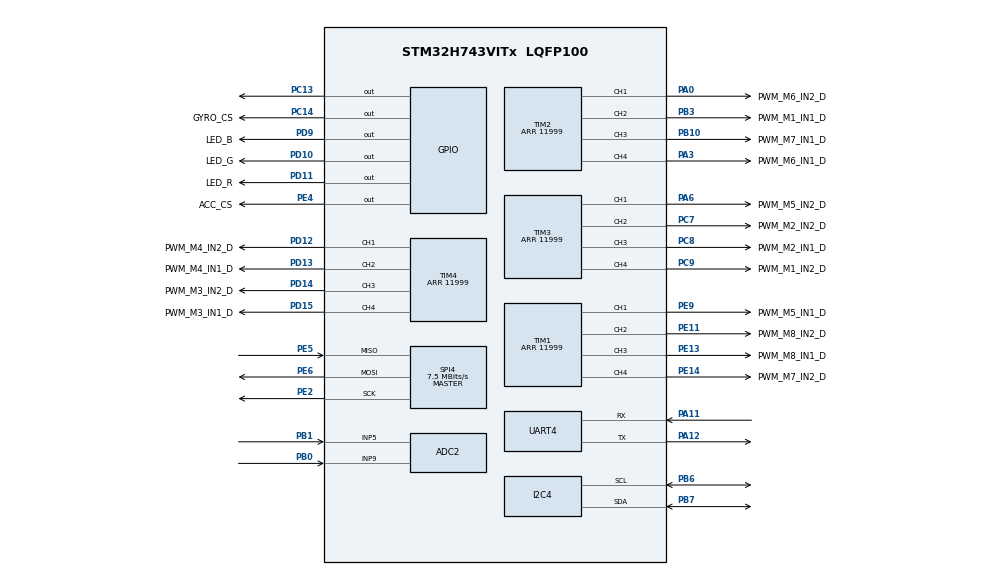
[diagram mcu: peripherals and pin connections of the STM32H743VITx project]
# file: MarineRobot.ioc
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ADC2.Channel-1\#ChannelRegularConversion=ADC_CHANNEL_9
ADC2.NbrOfConversionFlag=1
ADC2.OffsetNumber-1\#ChannelRegularConversion=ADC_OFFSET_NONE
ADC2.OffsetSignedSaturation-1\#ChannelRegularConversion=DISABLE
ADC2.Rank-1\#ChannelRegularConversion=1
ADC2.SamplingTime-1\#ChannelRegularConversion=ADC_SAMPLETIME_1CYCLE_5
CORTEX_M7.default_mode_Activation=1
FREERTOS.Tasks01=defaultTask,0,128,StartDefaultTask,Default,NULL,Dynamic,NULL,NULL
FREERTOS.configGENERATE_RUN_TIME_STATS=1
FREERTOS.configRECORD_STACK_HIGH_ADDRESS=1
FREERTOS.configUSE_STATS_FORMATTING_FUNCTIONS=1
FREERTOS.configUSE_TRACE_FACILITY=1
I2C4.Timing=0x307075B1
Mcu.Family=STM32H7
Mcu.Name=STM32H743VITx
Mcu.Package=LQFP100
NVIC.PriorityGroup=NVIC_PRIORITYGROUP_4
NVIC.TIM6_DAC_IRQn=true\:15\:0\:false\:false\:true\:false\:false\:true\:true
NVIC.TimeBase=TIM6_DAC_IRQn
NVIC.TimeBaseIP=TIM6
NVIC.UART4_IRQn=true\:5\:0\:false\:false\:true\:true\:true\:true\:true
PA0.GPIO_Label=PWM_M6_IN2_D
PA0.Signal=S_TIM2_CH1_ETR
PA11.Mode=Asynchronous
PA11.Signal=UART4_RX
PA12.Mode=Asynchronous
PA12.Signal=UART4_TX
PA13\ (JTMS/SWDIO).Mode=Serial_Wire
PA13\ (JTMS/SWDIO).Signal=DEBUG_JTMS-SWDIO
PA14\ (JTCK/SWCLK).Mode=Serial_Wire
PA14\ (JTCK/SWCLK).Signal=DEBUG_JTCK-SWCLK
PA3.GPIO_Label=PWM_M6_IN1_D
PA3.Signal=S_TIM2_CH4
PA6.GPIO_Label=PWM_M5_IN2_D
PA6.Signal=S_TIM3_CH1
PB0.Signal=ADCx_INP9
PB1.Signal=ADCx_INP5
PB10.GPIO_Label=PWM_M7_IN1_D
PB10.Signal=S_TIM2_CH3
PB3\ (JTDO/TRACESWO).GPIO_Label=PWM_M1_IN1_D
PB3\ (JTDO/TRACESWO).Signal=S_TIM2_CH2
PB6.Mode=I2C
PB6.Signal=I2C4_SCL
PB7.Mode=I2C
PB7.Signal=I2C4_SDA
PC12.Signal=UART5_TX
PC13.Signal=GPIO_Output
PC14-OSC32_IN\ (OSC32_IN).GPIO_Label=GYRO_CS
PC14-OSC32_IN\ (OSC32_IN).Signal=GPIO_Output
PC7.GPIO_Label=PWM_M2_IN2_D
PC7.Signal=S_TIM3_CH2
PC8.GPIO_Label=PWM_M2_IN1_D
PC8.Signal=S_TIM3_CH3
PC9.GPIO_Label=PWM_M1_IN2_D
PC9.Signal=S_TIM3_CH4
PD10.GPIO_Label=LED_G
PD10.Signal=GPIO_Output
PD11.GPIO_Label=LED_R
PD11.Signal=GPIO_Output
PD12.GPIO_Label=PWM_M4_IN2_D
PD12.Signal=S_TIM4_CH1
PD13.GPIO_Label=PWM_M4_IN1_D
PD13.Signal=S_TIM4_CH2
PD14.GPIO_Label=PWM_M3_IN2_D
PD14.Signal=S_TIM4_CH3
PD15.GPIO_Label=PWM_M3_IN1_D
PD15.Signal=S_TIM4_CH4
PD2.Signal=UART5_RX
PD9.GPIO_Label=LED_B
PD9.Signal=GPIO_Output
PE11.GPIO_Label=PWM_M8_IN2_D
PE11.Signal=S_TIM1_CH2
PE13.GPIO_Label=PWM_M8_IN1_D
PE13.Signal=S_TIM1_CH3
PE14.GPIO_Label=PWM_M7_IN2_D
PE14.Signal=S_TIM1_CH4
PE2.Mode=Full_Duplex_Master
PE2.Signal=SPI4_SCK
PE4.GPIO_Label=ACC_CS
PE4.Signal=GPIO_Output
PE5.Mode=Full_Duplex_Master
PE5.Signal=SPI4_MISO
PE6.Mode=Full_Duplex_Master
PE6.Signal=SPI4_MOSI
PE9.GPIO_Label=PWM_M5_IN1_D
PE9.Signal=S_TIM1_CH1
PH0-OSC_IN\ (PH0).Mode=HSE-External-Oscillator
PH0-OSC_IN\ (PH0).Signal=RCC_OSC_IN
PH1-OSC_OUT\ (PH1).Mode=HSE-External-Oscillator
PH1-OSC_OUT\ (PH1).Signal=RCC_OSC_OUT
ProjectManager.HeapSize=0x200
ProjectManager.StackSize=0x400
ProjectManager.TargetToolchain=CMake
RCC.ADCFreq_Value=80000000
RCC.APB1Freq_Value=120000000
RCC.APB2Freq_Value=120000000
RCC.APB3Freq_Value=120000000
RCC.APB4Freq_Value=120000000
RCC.CortexFreq_Value=480000000
RCC.D1PPRE=RCC_APB3_DIV2
RCC.D2PPRE1=RCC_APB1_DIV2
RCC.D2PPRE2=RCC_APB2_DIV2
RCC.D3PPRE=RCC_APB4_DIV2
RCC.DIVM1=2
RCC.DIVM2=2
RCC.DIVN1=60
RCC.DIVN2=10
RCC.HCLKFreq_Value=240000000
RCC.HPRE=RCC_HCLK_DIV2
RCC.HSE_VALUE=32000000
RCC.PLL2FRACN=0
RCC.PLLSourceVirtual=RCC_PLLSOURCE_HSE
RCC.SYSCLKFreq_VALUE=480000000
RCC.SYSCLKSource=RCC_SYSCLKSOURCE_PLLCLK
RCC.USBFreq_Value=480000000
SH.ADCx_INP5.0=ADC2_INP5,IN5-Single-Ended
SH.ADCx_INP9.0=ADC2_INP9,IN9-Single-Ended
SH.S_TIM1_CH1.0=TIM1_CH1,PWM Generation1 CH1
SH.S_TIM1_CH2.0=TIM1_CH2,PWM Generation2 CH2
SH.S_TIM1_CH3.0=TIM1_CH3,PWM Generation3 CH3
SH.S_TIM1_CH4.0=TIM1_CH4,PWM Generation4 CH4
SH.S_TIM2_CH1_ETR.0=TIM2_CH1,PWM Generation1 CH1
SH.S_TIM2_CH2.0=TIM2_CH2,PWM Generation2 CH2
SH.S_TIM2_CH3.0=TIM2_CH3,PWM Generation3 CH3
SH.S_TIM2_CH4.0=TIM2_CH4,PWM Generation4 CH4
SH.S_TIM3_CH1.0=TIM3_CH1,PWM Generation1 CH1
SH.S_TIM3_CH2.0=TIM3_CH2,PWM Generation2 CH2
SH.S_TIM3_CH3.0=TIM3_CH3,PWM Generation3 CH3
SH.S_TIM3_CH4.0=TIM3_CH4,PWM Generation4 CH4
SH.S_TIM4_CH1.0=TIM4_CH1,PWM Generation1 CH1
SH.S_TIM4_CH2.0=TIM4_CH2,PWM Generation2 CH2
SH.S_TIM4_CH3.0=TIM4_CH3,PWM Generation3 CH3
SH.S_TIM4_CH4.0=TIM4_CH4,PWM Generation4 CH4
SPI4.BaudRatePrescaler=SPI_BAUDRATEPRESCALER_16
SPI4.CalculateBaudRate=7.5 MBits/s
SPI4.DataSize=SPI_DATASIZE_8BIT
SPI4.Direction=SPI_DIRECTION_2LINES
SPI4.Mode=SPI_MODE_MASTER
SPI4.VirtualType=VM_MASTER
TIM1.Channel-PWM\ Generation1\ CH1=TIM_CHANNEL_1
TIM1.Channel-PWM\ Generation2\ CH2=TIM_CHANNEL_2
TIM1.Channel-PWM\ Generation3\ CH3=TIM_CHANNEL_3
TIM1.Channel-PWM\ Generation4\ CH4=TIM_CHANNEL_4
TIM1.Period=11999
TIM2.Channel-PWM\ Generation1\ CH1=TIM_CHANNEL_1
TIM2.Channel-PWM\ Generation2\ CH2=TIM_CHANNEL_2
TIM2.Channel-PWM\ Generation3\ CH3=TIM_CHANNEL_3
TIM2.Channel-PWM\ Generation4\ CH4=TIM_CHANNEL_4
TIM2.Period=11999
TIM3.Channel-PWM\ Generation1\ CH1=TIM_CHANNEL_1
TIM3.Channel-PWM\ Generation2\ CH2=TIM_CHANNEL_2
TIM3.Channel-PWM\ Generation3\ CH3=TIM_CHANNEL_3
TIM3.Channel-PWM\ Generation4\ CH4=TIM_CHANNEL_4
TIM3.Period=11999
TIM4.Channel-PWM\ Generation1\ CH1=TIM_CHANNEL_1
TIM4.Channel-PWM\ Generation2\ CH2=TIM_CHANNEL_2
TIM4.Channel-PWM\ Generation3\ CH3=TIM_CHANNEL_3
TIM4.Channel-PWM\ Generation4\ CH4=TIM_CHANNEL_4
TIM4.Period=11999
VP_FREERTOS_VS_CMSIS_V1.Mode=CMSIS_V1
VP_MEMORYMAP_VS_MEMORYMAP.Mode=CurAppReg
VP_SYS_VS_tim6.Mode=TIM6
VP_TIM1_VS_ClockSourceINT.Mode=Internal
VP_TIM2_VS_ClockSourceINT.Mode=Internal
VP_TIM3_VS_ClockSourceINT.Mode=Internal
VP_TIM4_VS_ClockSourceINT.Mode=Internal
board=custom

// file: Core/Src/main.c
/* USER CODE BEGIN Header */
/**
  ******************************************************************************
  * @file           : main.c
  * @brief          : Main program body
  ******************************************************************************
  * @attention
  *
  * Copyright (c) 2025 STMicroelectronics.
  * All rights reserved.
  *
  * This software is licensed under terms that can be found in the LICENSE file
  * in the root directory of this software component.
  * If no LICENSE file comes with this software, it is provided AS-IS.
  *
  ******************************************************************************
  */
/* USER CODE END Header */
#include "main.h"
#include "cmsis_os.h"
#include "adc.h"
#include "i2c.h"
#include "spi.h"
#include "tim.h"
#include "usart.h"
#include "gpio.h"

void SystemClock_Config(void);
static void MPU_Config(void);
void MX_FREERTOS_Init(void);

int main(void)
{

  /* MPU Configuration--------------------------------------------------------*/
  MPU_Config();

  /* MCU Configuration--------------------------------------------------------*/

  /* Reset of all peripherals, Initializes the Flash interface and the Systick. */
  HAL_Init();

  /* Configure the system clock */
  SystemClock_Config();

  /* Initialize all configured peripherals */
  MX_GPIO_Init();
  MX_TIM1_Init();
  MX_ADC2_Init();
  MX_I2C4_Init();
  MX_SPI4_Init();
  MX_TIM2_Init();
  MX_TIM3_Init();
  MX_TIM4_Init();
  MX_UART4_Init();

  /* Call init function for freertos objects (in cmsis_os2.c) */
  MX_FREERTOS_Init();

  /* Start scheduler */
  osKernelStart();

  /* We should never get here as control is now taken by the scheduler */

  /* Infinite loop */
  while (1)
  {

  }
}

void SystemClock_Config(void)
{
  RCC_OscInitTypeDef RCC_OscInitStruct = {0};
  RCC_ClkInitTypeDef RCC_ClkInitStruct = {0};

  /** Supply configuration update enable
  */
  HAL_PWREx_ConfigSupply(PWR_LDO_SUPPLY);

  /** Configure the main internal regulator output voltage
  */
  __HAL_PWR_VOLTAGESCALING_CONFIG(PWR_REGULATOR_VOLTAGE_SCALE0);

  while(!__HAL_PWR_GET_FLAG(PWR_FLAG_VOSRDY)) {}

  /** Initializes the RCC Oscillators according to the specified parameters
  * in the RCC_OscInitTypeDef structure.
  */
  RCC_OscInitStruct.OscillatorType = RCC_OSCILLATORTYPE_HSE;
  RCC_OscInitStruct.HSEState = RCC_HSE_ON;
  RCC_OscInitStruct.PLL.PLLState = RCC_PLL_ON;
  RCC_OscInitStruct.PLL.PLLSource = RCC_PLLSOURCE_HSE;
  RCC_OscInitStruct.PLL.PLLM = 2;
  RCC_OscInitStruct.PLL.PLLN = 60;
  RCC_OscInitStruct.PLL.PLLP = 2;
  RCC_OscInitStruct.PLL.PLLQ = 2;
  RCC_OscInitStruct.PLL.PLLR = 2;
  RCC_OscInitStruct.PLL.PLLRGE = RCC_PLL1VCIRANGE_3;
  RCC_OscInitStruct.PLL.PLLVCOSEL = RCC_PLL1VCOWIDE;
  RCC_OscInitStruct.PLL.PLLFRACN = 0;
  if (HAL_RCC_OscConfig(&RCC_OscInitStruct) != HAL_OK)
  {
    Error_Handler();
  }

  /** Initializes the CPU, AHB and APB buses clocks
  */
  RCC_ClkInitStruct.ClockType = RCC_CLOCKTYPE_HCLK|RCC_CLOCKTYPE_SYSCLK
                              |RCC_CLOCKTYPE_PCLK1|RCC_CLOCKTYPE_PCLK2
                              |RCC_CLOCKTYPE_D3PCLK1|RCC_CLOCKTYPE_D1PCLK1;
  RCC_ClkInitStruct.SYSCLKSource = RCC_SYSCLKSOURCE_PLLCLK;
  RCC_ClkInitStruct.SYSCLKDivider = RCC_SYSCLK_DIV1;
  RCC_ClkInitStruct.AHBCLKDivider = RCC_HCLK_DIV2;
  RCC_ClkInitStruct.APB3CLKDivider = RCC_APB3_DIV2;
  RCC_ClkInitStruct.APB1CLKDivider = RCC_APB1_DIV2;
  RCC_ClkInitStruct.APB2CLKDivider = RCC_APB2_DIV2;
  RCC_ClkInitStruct.APB4CLKDivider = RCC_APB4_DIV2;

  if (HAL_RCC_ClockConfig(&RCC_ClkInitStruct, FLASH_LATENCY_4) != HAL_OK)
  {
    Error_Handler();
  }
}

 /* MPU Configuration */

void MPU_Config(void)
{
  MPU_Region_InitTypeDef MPU_InitStruct = {0};

  /* Disables the MPU */
  HAL_MPU_Disable();

  /** Initializes and configures the Region and the memory to be protected
  */
  MPU_InitStruct.Enable = MPU_REGION_ENABLE;
  MPU_InitStruct.Number = MPU_REGION_NUMBER0;
  MPU_InitStruct.BaseAddress = 0x0;
  MPU_InitStruct.Size = MPU_REGION_SIZE_4GB;
  MPU_InitStruct.SubRegionDisable = 0x87;
  MPU_InitStruct.TypeExtField = MPU_TEX_LEVEL0;
  MPU_InitStruct.AccessPermission = MPU_REGION_NO_ACCESS;
  MPU_InitStruct.DisableExec = MPU_INSTRUCTION_ACCESS_DISABLE;
  MPU_InitStruct.IsShareable = MPU_ACCESS_SHAREABLE;
  MPU_InitStruct.IsCacheable = MPU_ACCESS_NOT_CACHEABLE;
  MPU_InitStruct.IsBufferable = MPU_ACCESS_NOT_BUFFERABLE;

  HAL_MPU_ConfigRegion(&MPU_InitStruct);
  /* Enables the MPU */
  HAL_MPU_Enable(MPU_PRIVILEGED_DEFAULT);

}

void HAL_TIM_PeriodElapsedCallback(TIM_HandleTypeDef *htim)
{
  if (htim->Instance == TIM6)
  {
    HAL_IncTick();
  }
}

void Error_Handler(void)
{
  __disable_irq();
  while (1)
  {
  }
}

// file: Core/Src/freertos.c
/* USER CODE BEGIN Header */
/**
  ******************************************************************************
  * File Name          : freertos.c
  * Description        : Code for freertos applications
  ******************************************************************************
  * @attention
  *
  * Copyright (c) 2025 STMicroelectronics.
  * All rights reserved.
  *
  * This software is licensed under terms that can be found in the LICENSE file
  * in the root directory of this software component.
  * If no LICENSE file comes with this software, it is provided AS-IS.
  *
  ******************************************************************************
  */
/* USER CODE END Header */

#include "FreeRTOS.h"
#include "task.h"
#include "main.h"
#include "cmsis_os.h"

/* USER CODE BEGIN Includes */
#include "app_main.h"
/* USER CODE END Includes */

osThreadId defaultTaskHandle;

void StartDefaultTask(void const * argument);

void MX_FREERTOS_Init(void); /* (MISRA C 2004 rule 8.1) */

/* GetIdleTaskMemory prototype (linked to static allocation support) */
void vApplicationGetIdleTaskMemory( StaticTask_t **ppxIdleTaskTCBBuffer, StackType_t **ppxIdleTaskStackBuffer, uint32_t *pulIdleTaskStackSize );

/* Hook prototypes */
void configureTimerForRunTimeStats(void);
unsigned long getRunTimeCounterValue(void);

/* USER CODE BEGIN 1 */
/* Functions needed when configGENERATE_RUN_TIME_STATS is on */
__weak void configureTimerForRunTimeStats(void)
{

}

__weak unsigned long getRunTimeCounterValue(void)
{
return 0;
}
/* USER CODE END 1 */

/* USER CODE BEGIN GET_IDLE_TASK_MEMORY */
static StaticTask_t xIdleTaskTCBBuffer;
static StackType_t xIdleStack[configMINIMAL_STACK_SIZE];

void vApplicationGetIdleTaskMemory( StaticTask_t **ppxIdleTaskTCBBuffer, StackType_t **ppxIdleTaskStackBuffer, uint32_t *pulIdleTaskStackSize )
{
  *ppxIdleTaskTCBBuffer = &xIdleTaskTCBBuffer;
  *ppxIdleTaskStackBuffer = &xIdleStack[0];
  *pulIdleTaskStackSize = configMINIMAL_STACK_SIZE;
  /* place for user code */
}
/* USER CODE END GET_IDLE_TASK_MEMORY */

void MX_FREERTOS_Init(void) {

  /* Create the thread(s) */
  /* definition and creation of defaultTask */
  osThreadDef(defaultTask, StartDefaultTask, osPriorityNormal, 0, 128);
  defaultTaskHandle = osThreadCreate(osThread(defaultTask), NULL);

  /* USER CODE BEGIN RTOS_THREADS */
  /* add threads, ... */
  app_main_init();
  app_main_start();
  /* USER CODE END RTOS_THREADS */

}

void StartDefaultTask(void const * argument)
{
  for(;;)
  {
    osDelay(1);
  }
}
